# RK3399-AP register map
File version: 1
CPU: CA7 r0p1, little endian, MPU, FPU, I-cache, D-cache, VTOR, 4 interrupt priority bits, 0 interrupts
Registers are 32-bit, read-write, reset 0x0 unless marked. A register's access mark holds for its fields unless they carry their own. Offsets are from the block's base; [hi:lo] are bit positions; {n}, {i} and the like mark numbered series.

## CRU (part 3 of 3)
Base 0xFF760000
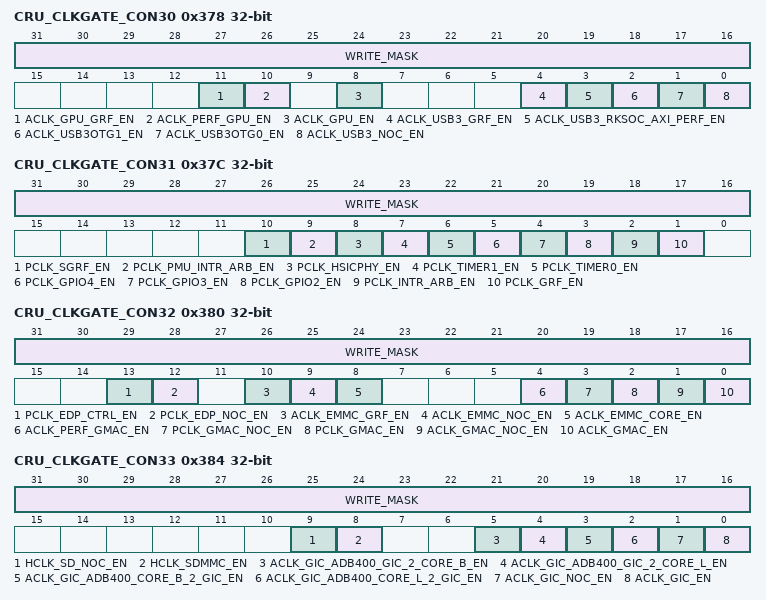
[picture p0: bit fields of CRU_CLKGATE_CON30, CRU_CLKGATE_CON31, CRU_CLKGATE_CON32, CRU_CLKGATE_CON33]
0x378 CRU_CLKGATE_CON30 access per field — Internal clock gating register30
  [31:16] WRITE_MASK wo — write mask bits When every bit HIGH, enable the writing corresponding bit When every bit LOW, don\'t care the writing corresponding bit
  [11] ACLK_GPU_GRF_EN rw — aclk_gpu_grf clock disable bit When HIGH, disable clock Suggest always on
  [10] ACLK_PERF_GPU_EN rw — aclk_perf_gpu clock disable bit When HIGH, disable clock
  [8] ACLK_GPU_EN rw — aclk_gpu clock disable bit When HIGH, disable clock
  [4] ACLK_USB3_GRF_EN rw — aclk_usb3_grf clock disable bit When HIGH, disable clock Suggest always on
  [3] ACLK_USB3_RKSOC_AXI_PERF_EN rw — aclk_usb3_rksoc_axi_perf clock disable bit When HIGH, disable clock
  [2] ACLK_USB3OTG1_EN rw — aclk_usb3otg1 clock disable bit When HIGH, disable clock
  [1] ACLK_USB3OTG0_EN rw — aclk_usb3otg0 clock disable bit When HIGH, disable clock
  [0] ACLK_USB3_NOC_EN rw — aclk_usb3_noc clock disable bit When HIGH, disable clock Suggest always on
0x37C CRU_CLKGATE_CON31 access per field — Internal clock gating register31
  [31:16] WRITE_MASK wo — write mask bits When every bit HIGH, enable the writing corresponding bit When every bit LOW, don\'t care the writing corresponding bit
  [10] PCLK_SGRF_EN rw — pclk_sgrf clock disable bit When HIGH, disable clock Suggest always on
  [9] PCLK_PMU_INTR_ARB_EN rw — pclk_pmu_intr_arb clock disable bit When HIGH, disable clock
  [8] PCLK_HSICPHY_EN rw — pclk_hsicphy clock disable bit When HIGH, disable clock
  [7] PCLK_TIMER1_EN rw — pclk_timer1 clock disable bit When HIGH, disable clock
  [6] PCLK_TIMER0_EN rw — pclk_timer0 clock disable bit When HIGH, disable clock
  [5] PCLK_GPIO4_EN rw — pclk_gpio4 clock disable bit When HIGH, disable clock
  [4] PCLK_GPIO3_EN rw — pclk_gpio3 clock disable bit When HIGH, disable clock
  [3] PCLK_GPIO2_EN rw — pclk_gpio2 clock disable bit When HIGH, disable clock
  [2] PCLK_INTR_ARB_EN rw — pclk_intr_arb clock disable bit When HIGH, disable clock
  [1] PCLK_GRF_EN rw — pclk_grf clock disable bit When HIGH, disable clock Suggest always on
0x380 CRU_CLKGATE_CON32 access per field — Internal clock gating register32
  [31:16] WRITE_MASK wo — write mask bits When every bit HIGH, enable the writing corresponding bit When every bit LOW, don\'t care the writing corresponding bit
  [13] PCLK_EDP_CTRL_EN rw — pclk_edp_ctrl clock disable bit When HIGH, disable clock
  [12] PCLK_EDP_NOC_EN rw — pclk_edp_noc clock disable bit When HIGH, disable clock Suggest always on
  [10] ACLK_EMMC_GRF_EN rw — aclk_emmc_grf clock disable bit When HIGH, disable clock Suggest always on
  [9] ACLK_EMMC_NOC_EN rw — aclk_emmc_noc clock disable bit When HIGH, disable clock Suggest always on
  [8] ACLK_EMMC_CORE_EN rw — aclk_emmc_core clock disable bit When HIGH, disable clock
  [4] ACLK_PERF_GMAC_EN rw — aclk_perf_gmac clock disable bit When HIGH, disable clock
  [3] PCLK_GMAC_NOC_EN rw — pclk_gmac_noc clock disable bit When HIGH, disable clock Suggest always on
  [2] PCLK_GMAC_EN rw — pclk_gmac clock disable bit When HIGH, disable clock
  [1] ACLK_GMAC_NOC_EN rw — aclk_gmac_noc clock disable bit When HIGH, disable clock Suggest always on
  [0] ACLK_GMAC_EN rw — aclk_gmac clock disable bit When HIGH, disable clock
0x384 CRU_CLKGATE_CON33 access per field — Internal clock gating register33
  [31:16] WRITE_MASK wo — write mask bits When every bit HIGH, enable the writing corresponding bit When every bit LOW, don\'t care the writing corresponding bit
  [9] HCLK_SD_NOC_EN rw — hclk_sd_noc clock disable bit When HIGH, disable clock Suggest always on
  [8] HCLK_SDMMC_EN rw — hclk_sdmmc clock disable bit When HIGH, disable clock
  [5] ACLK_GIC_ADB400_GIC_2_CORE_B_EN rw — aclk_gic_adb400_gic_2_core_b clock disable bit When HIGH, disable clock
  [4] ACLK_GIC_ADB400_GIC_2_CORE_L_EN rw — aclk_gic_adb400_gic_2_core_l clock disable bit When HIGH, disable clock
  [3] ACLK_GIC_ADB400_CORE_B_2_GIC_EN rw — aclk_gic_adb400_core_b_2_gic clock disable bit When HIGH, disable clock
  [2] ACLK_GIC_ADB400_CORE_L_2_GIC_EN rw — aclk_gic_adb400_core_l_2_gic clock disable bit When HIGH, disable clock
  [1] ACLK_GIC_NOC_EN rw — aclk_gic_noc clock disable bit When HIGH, disable clock Suggest always on
  [0] ACLK_GIC_EN rw — aclk_gic clock disable bit When HIGH, disable clock
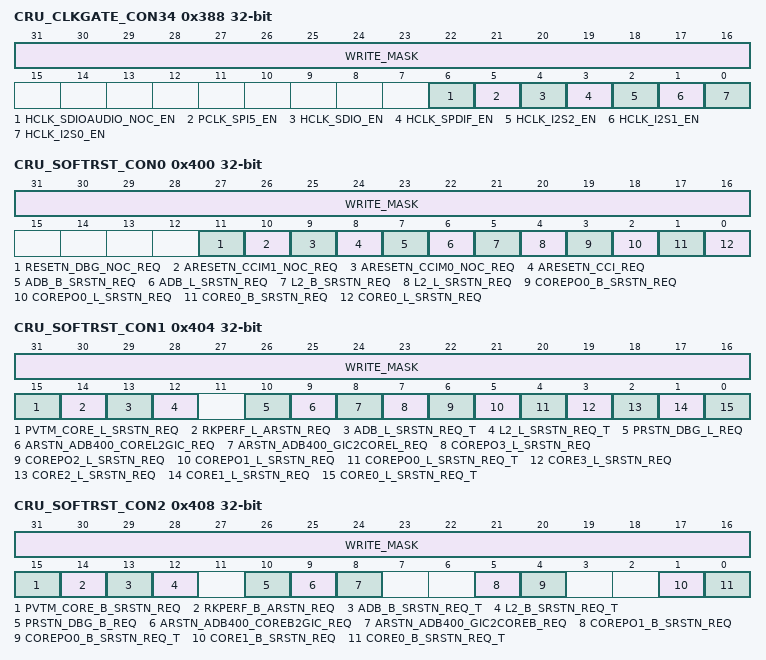
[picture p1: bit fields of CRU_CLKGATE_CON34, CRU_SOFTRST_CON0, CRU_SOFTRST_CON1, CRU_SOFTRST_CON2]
0x388 CRU_CLKGATE_CON34 access per field — Internal clock gating register34
  [31:16] WRITE_MASK wo — write mask bits When every bit HIGH, enable the writing corresponding bit When every bit LOW, don\'t care the writing corresponding bit
  [6] HCLK_SDIOAUDIO_NOC_EN rw — hclk_sdioaudio_noc clock disable bit When HIGH, disable clock Suggest always on
  [5] PCLK_SPI5_EN rw — pclk_spi5 clock disable bit When HIGH, disable clock
  [4] HCLK_SDIO_EN rw — hclk_sdio clock disable bit When HIGH, disable clock
  [3] HCLK_SPDIF_EN rw — hclk_spdif clock disable bit When HIGH, disable clock
  [2] HCLK_I2S2_EN rw — hclk_i2s2 clock disable bit When HIGH, disable clock
  [1] HCLK_I2S1_EN rw — hclk_i2s1 clock disable bit When HIGH, disable clock
  [0] HCLK_I2S0_EN rw — hclk_i2s0 clock disable bit When HIGH, disable clock
0x400 CRU_SOFTRST_CON0 wo — Internal software reset control register0
  [31:16] WRITE_MASK — write mask bits When every bit HIGH, enable the writing corresponding bit When every bit LOW, don\'t care the writing corresponding bit
  [11] RESETN_DBG_NOC_REQ write-clears — resetn_dbg_noc request bit When HIGH, reset relative logic
  [10] ARESETN_CCIM1_NOC_REQ write-clears — aresetn_ccim1_noc request bit When HIGH, reset relative logic
  [9] ARESETN_CCIM0_NOC_REQ write-clears — aresetn_ccim0_noc request bit When HIGH, reset relative logic
  [8] ARESETN_CCI_REQ write-clears — aresetn_cci request bit When HIGH, reset relative logic
  [7] ADB_B_SRSTN_REQ write-clears — adb_b_srstn request bit When HIGH, reset relative logic
  [6] ADB_L_SRSTN_REQ write-clears — adb_l_srstn request bit When HIGH, reset relative logic
  [5] L2_B_SRSTN_REQ write-clears — l2_b_srstn request bit When HIGH, reset relative logic
  [4] L2_L_SRSTN_REQ write-clears — l2_l_srstn request bit When HIGH, reset relative logic
  [3] COREPO0_B_SRSTN_REQ write-clears — corepo0_b_srstn request bit When HIGH, reset relative logic
  [2] COREPO0_L_SRSTN_REQ write-clears — corepo0_l_srstn request bit When HIGH, reset relative logic
  [1] CORE0_B_SRSTN_REQ write-clears — core0_b_srstn request bit When HIGH, reset relative logic
  [0] CORE0_L_SRSTN_REQ write-clears — core0_l_srstn request bit When HIGH, reset relative logic
0x404 CRU_SOFTRST_CON1 access per field — Internal software reset control register1
  [31:16] WRITE_MASK wo — write mask bits When every bit HIGH, enable the writing corresponding bit When every bit LOW, don\'t care the writing corresponding bit
  [15] PVTM_CORE_L_SRSTN_REQ rw — pvtm_core_l_srstn request bit When HIGH, reset relative logic
  [14] RKPERF_L_ARSTN_REQ rw — rkperf_l_arstn request bit When HIGH, reset relative logic
  [13] ADB_L_SRSTN_REQ_T rw — adb_l_srstn request bit When HIGH, reset relative logic
  [12] L2_L_SRSTN_REQ_T rw — l2_l_srstn request bit When HIGH, reset relative logic
  [10] PRSTN_DBG_L_REQ rw — prstn_dbg_l request bit When HIGH, reset relative logic
  [9] ARSTN_ADB400_COREL2GIC_REQ rw — arstn_adb400_corel2gic request bit When HIGH, reset relative logic
  [8] ARSTN_ADB400_GIC2COREL_REQ rw — arstn_adb400_gic2corel request bit When HIGH, reset relative logic
  [7] COREPO3_L_SRSTN_REQ rw — corepo3_l_srstn request bit When HIGH, reset relative logic
  [6] COREPO2_L_SRSTN_REQ rw — corepo2_l_srstn request bit When HIGH, reset relative logic
  [5] COREPO1_L_SRSTN_REQ rw — corepo1_l_srstn request bit When HIGH, reset relative logic
  [4] COREPO0_L_SRSTN_REQ_T rw — corepo0_l_srstn request bit When HIGH, reset relative logic
  [3] CORE3_L_SRSTN_REQ rw — core3_l_srstn request bit When HIGH, reset relative logic
  [2] CORE2_L_SRSTN_REQ rw — core2_l_srstn request bit When HIGH, reset relative logic
  [1] CORE1_L_SRSTN_REQ rw — core1_l_srstn request bit When HIGH, reset relative logic
  [0] CORE0_L_SRSTN_REQ_T rw — core0_l_srstn request bit When HIGH, reset relative logic
0x408 CRU_SOFTRST_CON2 access per field — Internal software reset control register2
  [31:16] WRITE_MASK wo — write mask bits When every bit HIGH, enable the writing corresponding bit When every bit LOW, don\'t care the writing corresponding bit
  [15] PVTM_CORE_B_SRSTN_REQ rw — pvtm_core_b_srstn request bit When HIGH, reset relative logic
  [14] RKPERF_B_ARSTN_REQ rw — rkperf_b_arstn request bit When HIGH, reset relative logic
  [13] ADB_B_SRSTN_REQ_T rw — adb_b_srstn request bit When HIGH, reset relative logic
  [12] L2_B_SRSTN_REQ_T rw — l2_b_srstn request bit When HIGH, reset relative logic
  [10] PRSTN_DBG_B_REQ rw — prstn_dbg_b request bit When HIGH, reset relative logic
  [9] ARSTN_ADB400_COREB2GIC_REQ rw — arstn_adb400_coreb2gic request bit When HIGH, reset relative logic
  [8] ARSTN_ADB400_GIC2COREB_REQ rw — arstn_adb400_gic2coreb request bit When HIGH, reset relative logic
  [5] COREPO1_B_SRSTN_REQ rw — corepo1_b_srstn request bit When HIGH, reset relative logic
  [4] COREPO0_B_SRSTN_REQ_T rw — corepo0_b_srstn request bit When HIGH, reset relative logic
  [1] CORE1_B_SRSTN_REQ rw — core1_b_srstn request bit When HIGH, reset relative logic
  [0] CORE0_B_SRSTN_REQ_T rw — core0_b_srstn request bit When HIGH, reset relative logic
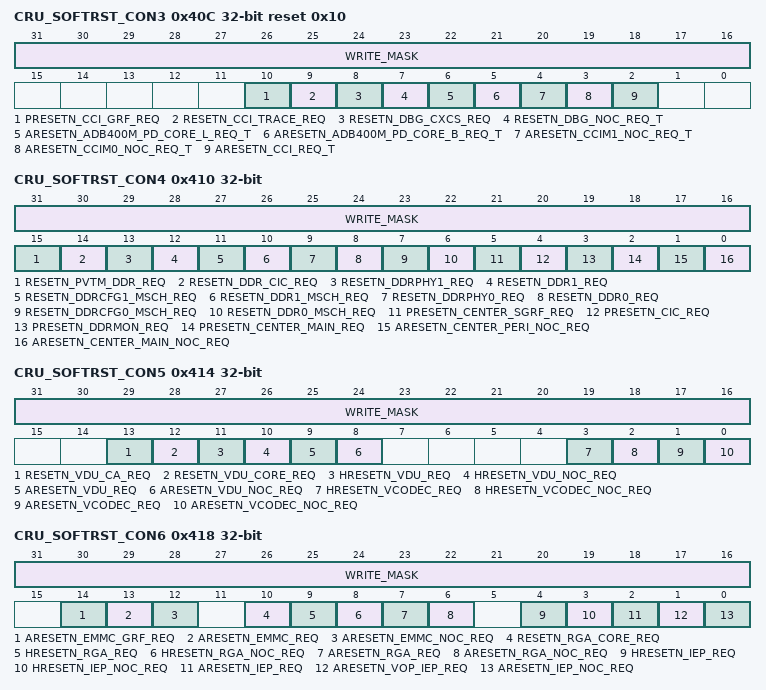
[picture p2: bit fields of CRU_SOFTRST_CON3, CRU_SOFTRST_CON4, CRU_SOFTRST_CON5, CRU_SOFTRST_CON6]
0x40C CRU_SOFTRST_CON3 access per field reset 0x10 — Internal software reset control register3
  [31:16] WRITE_MASK wo — write mask bits When every bit HIGH, enable the writing corresponding bit When every bit LOW, don\'t care the writing corresponding bit
  [10] PRESETN_CCI_GRF_REQ rw — presetn_cci_grf request bit When HIGH, reset relative logic
  [9] RESETN_CCI_TRACE_REQ rw — resetn_cci_trace request bit When HIGH, reset relative logic
  [8] RESETN_DBG_CXCS_REQ rw — resetn_dbg_cxcs request bit When HIGH, reset relative logic
  [7] RESETN_DBG_NOC_REQ_T rw — resetn_dbg_noc request bit When HIGH, reset relative logic
  [6] ARESETN_ADB400M_PD_CORE_L_REQ_T rw — aresetn_adb400m_pd_core_l request bit When HIGH, reset relative logic
  [5] ARESETN_ADB400M_PD_CORE_B_REQ_T rw — aresetn_adb400m_pd_core_b request bit When HIGH, reset relative logic
  [4] ARESETN_CCIM1_NOC_REQ_T ro — aresetn_ccim1_noc request bit When HIGH, reset relative logic
  [3] ARESETN_CCIM0_NOC_REQ_T rw — aresetn_ccim0_noc request bit When HIGH, reset relative logic
  [2] ARESETN_CCI_REQ_T rw — aresetn_cci request bit When HIGH, reset relative logic
0x410 CRU_SOFTRST_CON4 access per field — Internal software reset control register4
  [31:16] WRITE_MASK wo — write mask bits When every bit HIGH, enable the writing corresponding bit When every bit LOW, don\'t care the writing corresponding bit
  [15] RESETN_PVTM_DDR_REQ rw — resetn_pvtm_ddr request bit When HIGH, reset relative logic
  [14] RESETN_DDR_CIC_REQ rw — resetn_ddr_cic request bit When HIGH, reset relative logic
  [13] RESETN_DDRPHY1_REQ rw — resetn_ddrphy1 request bit When HIGH, reset relative logic
  [12] RESETN_DDR1_REQ rw — resetn_ddr1 request bit When HIGH, reset relative logic
  [11] RESETN_DDRCFG1_MSCH_REQ rw — resetn_ddrcfg1_msch request bit When HIGH, reset relative logic
  [10] RESETN_DDR1_MSCH_REQ rw — resetn_ddr1_msch request bit When HIGH, reset relative logic
  [9] RESETN_DDRPHY0_REQ rw — resetn_ddrphy0 request bit When HIGH, reset relative logic
  [8] RESETN_DDR0_REQ rw — resetn_ddr0 request bit When HIGH, reset relative logic
  [7] RESETN_DDRCFG0_MSCH_REQ rw — resetn_ddrcfg0_msch request bit When HIGH, reset relative logic
  [6] RESETN_DDR0_MSCH_REQ rw — resetn_ddr0_msch request bit When HIGH, reset relative logic
  [5] PRESETN_CENTER_SGRF_REQ rw — presetn_center_sgrf request bit When HIGH, reset relative logic
  [4] PRESETN_CIC_REQ rw — presetn_cic request bit When HIGH, reset relative logic
  [3] PRESETN_DDRMON_REQ rw — presetn_ddrmon request bit When HIGH, reset relative logic
  [2] PRESETN_CENTER_MAIN_REQ rw — presetn_center_main request bit When HIGH, reset relative logic
  [1] ARESETN_CENTER_PERI_NOC_REQ rw — aresetn_center_peri_noc request bit When HIGH, reset relative logic
  [0] ARESETN_CENTER_MAIN_NOC_REQ rw — aresetn_center_main_noc request bit When HIGH, reset relative logic
0x414 CRU_SOFTRST_CON5 access per field — Internal software reset control register5
  [31:16] WRITE_MASK wo — write mask bits When every bit HIGH, enable the writing corresponding bit When every bit LOW, don\'t care the writing corresponding bit
  [13] RESETN_VDU_CA_REQ rw — resetn_vdu_ca request bit When HIGH, reset relative logic
  [12] RESETN_VDU_CORE_REQ rw — resetn_vdu_core request bit When HIGH, reset relative logic
  [11] HRESETN_VDU_REQ rw — hresetn_vdu request bit When HIGH, reset relative logic
  [10] HRESETN_VDU_NOC_REQ rw — hresetn_vdu_noc request bit When HIGH, reset relative logic
  [9] ARESETN_VDU_REQ rw — aresetn_vdu request bit When HIGH, reset relative logic
  [8] ARESETN_VDU_NOC_REQ rw — aresetn_vdu_noc request bit When HIGH, reset relative logic
  [3] HRESETN_VCODEC_REQ rw — hresetn_vcodec request bit When HIGH, reset relative logic
  [2] HRESETN_VCODEC_NOC_REQ rw — hresetn_vcodec_noc request bit When HIGH, reset relative logic
  [1] ARESETN_VCODEC_REQ rw — aresetn_vcodec request bit When HIGH, reset relative logic
  [0] ARESETN_VCODEC_NOC_REQ rw — aresetn_vcodec_noc request bit When HIGH, reset relative logic
0x418 CRU_SOFTRST_CON6 access per field — Internal software reset control register6
  [31:16] WRITE_MASK wo — write mask bits When every bit HIGH, enable the writing corresponding bit When every bit LOW, don\'t care the writing corresponding bit
  [14] ARESETN_EMMC_GRF_REQ rw — aresetn_emmc_grf request bit When HIGH, reset relative logic
  [13] ARESETN_EMMC_REQ rw — aresetn_emmc request bit When HIGH, reset relative logic
  [12] ARESETN_EMMC_NOC_REQ rw — aresetn_emmc_noc request bit When HIGH, reset relative logic
  [10] RESETN_RGA_CORE_REQ rw — resetn_rga_core request bit When HIGH, reset relative logic
  [9] HRESETN_RGA_REQ rw — hresetn_rga request bit When HIGH, reset relative logic
  [8] HRESETN_RGA_NOC_REQ rw — hresetn_rga_noc request bit When HIGH, reset relative logic
  [7] ARESETN_RGA_REQ rw — aresetn_rga request bit When HIGH, reset relative logic
  [6] ARESETN_RGA_NOC_REQ rw — aresetn_rga_noc request bit When HIGH, reset relative logic
  [4] HRESETN_IEP_REQ rw — hresetn_iep request bit When HIGH, reset relative logic
  [3] HRESETN_IEP_NOC_REQ rw — hresetn_iep_noc request bit When HIGH, reset relative logic
  [2] ARESETN_IEP_REQ rw — aresetn_iep request bit When HIGH, reset relative logic
  [1] ARESETN_VOP_IEP_REQ rw — aresetn_vop_iep request bit When HIGH, reset relative logic
  [0] ARESETN_IEP_NOC_REQ rw — aresetn_iep_noc request bit When HIGH, reset relative logic
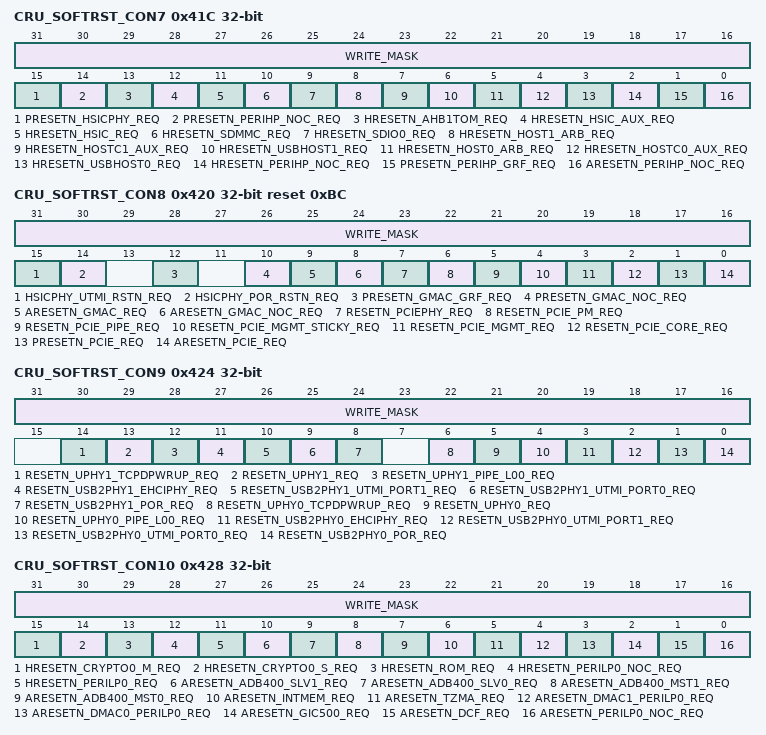
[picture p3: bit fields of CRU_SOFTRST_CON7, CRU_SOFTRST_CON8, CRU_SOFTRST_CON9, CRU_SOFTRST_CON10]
0x41C CRU_SOFTRST_CON7 access per field — Internal software reset control register7
  [31:16] WRITE_MASK wo — write mask bits When every bit HIGH, enable the writing corresponding bit When every bit LOW, don\'t care the writing corresponding bit
  [15] PRESETN_HSICPHY_REQ rw — presetn_hsicphy request bit When HIGH, reset relative logic
  [14] PRESETN_PERIHP_NOC_REQ rw — presetn_perihp_noc request bit When HIGH, reset relative logic
  [13] HRESETN_AHB1TOM_REQ rw — hresetn_ahb1tom request bit When HIGH, reset relative logic
  [12] HRESETN_HSIC_AUX_REQ rw — hresetn_hsic_aux request bit When HIGH, reset relative logic
  [11] HRESETN_HSIC_REQ rw — hresetn_hsic request bit When HIGH, reset relative logic
  [10] HRESETN_SDMMC_REQ rw — hresetn_sdmmc request bit When HIGH, reset relative logic
  [9] HRESETN_SDIO0_REQ rw — hresetn_sdio0 request bit When HIGH, reset relative logic
  [8] HRESETN_HOST1_ARB_REQ rw — hresetn_host1_arb request bit When HIGH, reset relative logic
  [7] HRESETN_HOSTC1_AUX_REQ rw — hresetn_hostc1_aux request bit When HIGH, reset relative logic
  [6] HRESETN_USBHOST1_REQ rw — hresetn_usbhost1 request bit When HIGH, reset relative logic
  [5] HRESETN_HOST0_ARB_REQ rw — hresetn_host0_arb request bit When HIGH, reset relative logic
  [4] HRESETN_HOSTC0_AUX_REQ rw — hresetn_hostc0_aux request bit When HIGH, reset relative logic
  [3] HRESETN_USBHOST0_REQ rw — hresetn_usbhost0 request bit When HIGH, reset relative logic
  [2] HRESETN_PERIHP_NOC_REQ rw — hresetn_perihp_noc request bit When HIGH, reset relative logic
  [1] PRESETN_PERIHP_GRF_REQ rw — presetn_perihp_grf request bit When HIGH, reset relative logic
  [0] ARESETN_PERIHP_NOC_REQ rw — aresetn_perihp_noc request bit When HIGH, reset relative logic
0x420 CRU_SOFTRST_CON8 access per field reset 0xBC — Internal software reset control register8
  [31:16] WRITE_MASK wo — write mask bits When every bit HIGH, enable the writing corresponding bit When every bit LOW, don\'t care the writing corresponding bit
  [15] HSICPHY_UTMI_RSTN_REQ rw — hsicphy_utmi_rstn request bit When HIGH, reset relative logic
  [14] HSICPHY_POR_RSTN_REQ rw — hsicphy_por_rstn request bit When HIGH, reset relative logic
  [12] PRESETN_GMAC_GRF_REQ rw — presetn_gmac_grf request bit When HIGH, reset relative logic
  [10] PRESETN_GMAC_NOC_REQ rw — presetn_gmac_noc request bit When HIGH, reset relative logic
  [9] ARESETN_GMAC_REQ rw — aresetn_gmac request bit When HIGH, reset relative logic
  [8] ARESETN_GMAC_NOC_REQ rw — aresetn_gmac_noc request bit When HIGH, reset relative logic
  [7] RESETN_PCIEPHY_REQ rw — resetn_pciephy request bit When HIGH, reset relative logic
  [6] RESETN_PCIE_PM_REQ rw — resetn_pcie_pm request bit When HIGH, reset relative logic
  [5] RESETN_PCIE_PIPE_REQ rw — resetn_pcie_pipe request bit When HIGH, reset relative logic
  [4] RESETN_PCIE_MGMT_STICKY_REQ rw — resetn_pcie_mgmt_sticky request bit When HIGH, reset relative logic
  [3] RESETN_PCIE_MGMT_REQ rw — resetn_pcie_mgmt request bit When HIGH, reset relative logic
  [2] RESETN_PCIE_CORE_REQ rw — resetn_pcie_core request bit When HIGH, reset relative logic
  [1] PRESETN_PCIE_REQ rw — presetn_pcie request bit When HIGH, reset relative logic
  [0] ARESETN_PCIE_REQ rw — aresetn_pcie request bit When HIGH, reset relative logic
0x424 CRU_SOFTRST_CON9 access per field — Internal software reset control register9
  [31:16] WRITE_MASK wo — write mask bits When every bit HIGH, enable the writing corresponding bit When every bit LOW, don\'t care the writing corresponding bit
  [14] RESETN_UPHY1_TCPDPWRUP_REQ rw — resetn_uphy1_tcpdpwrup request bit When HIGH, reset relative logic
  [13] RESETN_UPHY1_REQ rw — resetn_uphy1 request bit When HIGH, reset relative logic
  [12] RESETN_UPHY1_PIPE_L00_REQ rw — resetn_uphy1_pipe_l00 request bit When HIGH, reset relative logic
  [11] RESETN_USB2PHY1_EHCIPHY_REQ rw — resetn_usb2phy1_ehciphy request bit When HIGH, reset relative logic
  [10] RESETN_USB2PHY1_UTMI_PORT1_REQ rw — resetn_usb2phy1_utmi_port1 request bit When HIGH, reset relative logic
  [9] RESETN_USB2PHY1_UTMI_PORT0_REQ rw — resetn_usb2phy1_utmi_port0 request bit When HIGH, reset relative logic
  [8] RESETN_USB2PHY1_POR_REQ rw — resetn_usb2phy1_por request bit When HIGH, reset relative logic
  [6] RESETN_UPHY0_TCPDPWRUP_REQ rw — resetn_uphy0_tcpdpwrup request bit When HIGH, reset relative logic
  [5] RESETN_UPHY0_REQ rw — resetn_uphy0 request bit When HIGH, reset relative logic
  [4] RESETN_UPHY0_PIPE_L00_REQ rw — resetn_uphy0_pipe_l00 request bit When HIGH, reset relative logic
  [3] RESETN_USB2PHY0_EHCIPHY_REQ rw — resetn_usb2phy0_ehciphy request bit When HIGH, reset relative logic
  [2] RESETN_USB2PHY0_UTMI_PORT1_REQ rw — resetn_usb2phy0_utmi_port1 request bit When HIGH, reset relative logic
  [1] RESETN_USB2PHY0_UTMI_PORT0_REQ rw — resetn_usb2phy0_utmi_port0 request bit When HIGH, reset relative logic
  [0] RESETN_USB2PHY0_POR_REQ rw — resetn_usb2phy0_por request bit When HIGH, reset relative logic
0x428 CRU_SOFTRST_CON10 access per field — Internal software reset control register10
  [31:16] WRITE_MASK wo — write mask bits When every bit HIGH, enable the writing corresponding bit When every bit LOW, don\'t care the writing corresponding bit
  [15] HRESETN_CRYPTO0_M_REQ rw — hresetn_crypto0_m request bit When HIGH, reset relative logic
  [14] HRESETN_CRYPTO0_S_REQ rw — hresetn_crypto0_s request bit When HIGH, reset relative logic
  [13] HRESETN_ROM_REQ rw — hresetn_rom request bit When HIGH, reset relative logic
  [12] HRESETN_PERILP0_NOC_REQ rw — hresetn_perilp0_noc request bit When HIGH, reset relative logic
  [11] HRESETN_PERILP0_REQ rw — hresetn_perilp0 request bit When HIGH, reset relative logic
  [10] ARESETN_ADB400_SLV1_REQ rw — aresetn_adb400_slv1 request bit When HIGH, reset relative logic
  [9] ARESETN_ADB400_SLV0_REQ rw — aresetn_adb400_slv0 request bit When HIGH, reset relative logic
  [8] ARESETN_ADB400_MST1_REQ rw — aresetn_adb400_mst1 request bit When HIGH, reset relative logic
  [7] ARESETN_ADB400_MST0_REQ rw — aresetn_adb400_mst0 request bit When HIGH, reset relative logic
  [6] ARESETN_INTMEM_REQ rw — aresetn_intmem request bit When HIGH, reset relative logic
  [5] ARESETN_TZMA_REQ rw — aresetn_tzma request bit When HIGH, reset relative logic
  [4] ARESETN_DMAC1_PERILP0_REQ rw — aresetn_dmac1_perilp0 request bit When HIGH, reset relative logic
  [3] ARESETN_DMAC0_PERILP0_REQ rw — aresetn_dmac0_perilp0 request bit When HIGH, reset relative logic
  [2] ARESETN_GIC500_REQ rw — aresetn_gic500 request bit When HIGH, reset relative logic
  [1] ARESETN_DCF_REQ rw — aresetn_dcf request bit When HIGH, reset relative logic
  [0] ARESETN_PERILP0_NOC_REQ rw — aresetn_perilp0_noc request bit When HIGH, reset relative logic
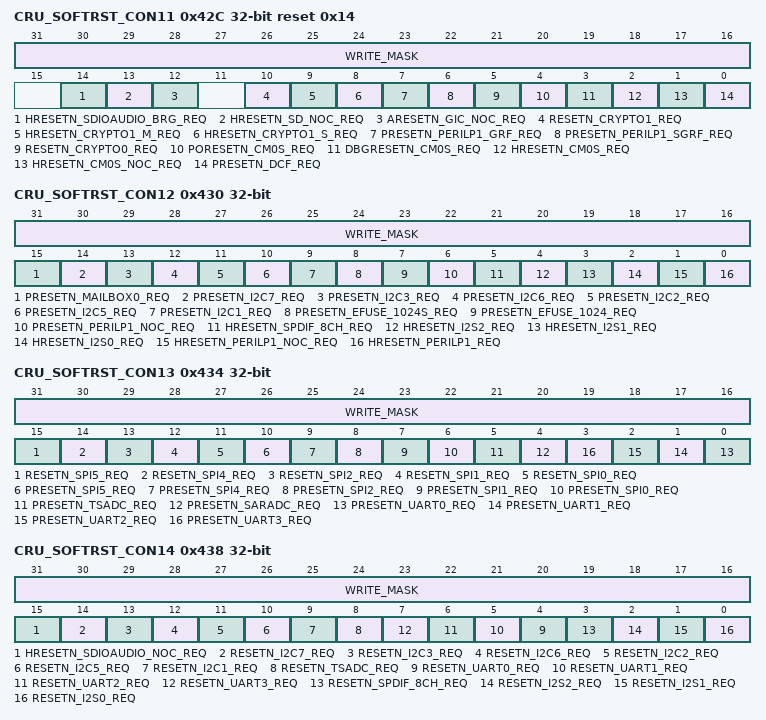
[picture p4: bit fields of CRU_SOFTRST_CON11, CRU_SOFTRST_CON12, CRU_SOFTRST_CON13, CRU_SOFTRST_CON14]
0x42C CRU_SOFTRST_CON11 access per field reset 0x14 — Internal software reset control register11
  [31:16] WRITE_MASK wo — write mask bits When every bit HIGH, enable the writing corresponding bit When every bit LOW, don\'t care the writing corresponding bit
  [14] HRESETN_SDIOAUDIO_BRG_REQ rw — hresetn_sdioaudio_brg request bit When HIGH, reset relative logic
  [13] HRESETN_SD_NOC_REQ rw — hresetn_sd_noc request bit When HIGH, reset relative logic
  [12] ARESETN_GIC_NOC_REQ rw — aresetn_gic_noc request bit When HIGH, reset relative logic
  [10] RESETN_CRYPTO1_REQ rw — resetn_crypto1 request bit When HIGH, reset relative logic
  [9] HRESETN_CRYPTO1_M_REQ rw — hresetn_crypto1_m request bit When HIGH, reset relative logic
  [8] HRESETN_CRYPTO1_S_REQ rw — hresetn_crypto1_s request bit When HIGH, reset relative logic
  [7] PRESETN_PERILP1_GRF_REQ rw — presetn_perilp1_grf request bit When HIGH, reset relative logic
  [6] PRESETN_PERILP1_SGRF_REQ rw — presetn_perilp1_sgrf request bit When HIGH, reset relative logic
  [5] RESETN_CRYPTO0_REQ rw — resetn_crypto0 request bit When HIGH, reset relative logic
  [4] PORESETN_CM0S_REQ rw — poresetn_cm0s request bit When HIGH, reset relative logic
  [3] DBGRESETN_CM0S_REQ rw — dbgresetn_cm0s request bit When HIGH, reset relative logic
  [2] HRESETN_CM0S_REQ rw — hresetn_cm0s request bit When HIGH, reset relative logic
  [1] HRESETN_CM0S_NOC_REQ rw — hresetn_cm0s_noc request bit When HIGH, reset relative logic
  [0] PRESETN_DCF_REQ rw — presetn_dcf request bit When HIGH, reset relative logic
0x430 CRU_SOFTRST_CON12 access per field — Internal software reset control register12
  [31:16] WRITE_MASK wo — write mask bits When every bit HIGH, enable the writing corresponding bit When every bit LOW, don\'t care the writing corresponding bit
  [15] PRESETN_MAILBOX0_REQ rw — presetn_mailbox0 request bit When HIGH, reset relative logic
  [14] PRESETN_I2C7_REQ rw — presetn_i2c7 request bit When HIGH, reset relative logic
  [13] PRESETN_I2C3_REQ rw — presetn_i2c3 request bit When HIGH, reset relative logic
  [12] PRESETN_I2C6_REQ rw — presetn_i2c6 request bit When HIGH, reset relative logic
  [11] PRESETN_I2C2_REQ rw — presetn_i2c2 request bit When HIGH, reset relative logic
  [10] PRESETN_I2C5_REQ rw — presetn_i2c5 request bit When HIGH, reset relative logic
  [9] PRESETN_I2C1_REQ rw — presetn_i2c1 request bit When HIGH, reset relative logic
  [8] PRESETN_EFUSE_1024S_REQ rw — presetn_efuse_1024s request bit When HIGH, reset relative logic
  [7] PRESETN_EFUSE_1024_REQ rw — presetn_efuse_1024 request bit When HIGH, reset relative logic
  [6] PRESETN_PERILP1_NOC_REQ rw — presetn_perilp1_noc request bit When HIGH, reset relative logic
  [5] HRESETN_SPDIF_8CH_REQ rw — hresetn_spdif_8ch request bit When HIGH, reset relative logic
  [4] HRESETN_I2S2_REQ rw — hresetn_i2s2 request bit When HIGH, reset relative logic
  [3] HRESETN_I2S1_REQ rw — hresetn_i2s1 request bit When HIGH, reset relative logic
  [2] HRESETN_I2S0_REQ rw — hresetn_i2s0 request bit When HIGH, reset relative logic
  [1] HRESETN_PERILP1_NOC_REQ rw — hresetn_perilp1_noc request bit When HIGH, reset relative logic
  [0] HRESETN_PERILP1_REQ rw — hresetn_perilp1 request bit When HIGH, reset relative logic
0x434 CRU_SOFTRST_CON13 access per field — Internal software reset control register13
  [31:16] WRITE_MASK wo — write mask bits When every bit HIGH, enable the writing corresponding bit When every bit LOW, don\'t care the writing corresponding bit
  [15] RESETN_SPI5_REQ rw — resetn_spi5 request bit When HIGH, reset relative logic
  [14] RESETN_SPI4_REQ rw — resetn_spi4 request bit When HIGH, reset relative logic
  [13] RESETN_SPI2_REQ rw — resetn_spi2 request bit When HIGH, reset relative logic
  [12] RESETN_SPI1_REQ rw — resetn_spi1 request bit When HIGH, reset relative logic
  [11] RESETN_SPI0_REQ rw — resetn_spi0 request bit When HIGH, reset relative logic
  [10] PRESETN_SPI5_REQ rw — presetn_spi5 request bit When HIGH, reset relative logic
  [9] PRESETN_SPI4_REQ rw — presetn_spi4 request bit When HIGH, reset relative logic
  [8] PRESETN_SPI2_REQ rw — presetn_spi2 request bit When HIGH, reset relative logic
  [7] PRESETN_SPI1_REQ rw — presetn_spi1 request bit When HIGH, reset relative logic
  [6] PRESETN_SPI0_REQ rw — presetn_spi0 request bit When HIGH, reset relative logic
  [5] PRESETN_TSADC_REQ rw — presetn_tsadc request bit When HIGH, reset relative logic
  [4] PRESETN_SARADC_REQ rw — presetn_saradc request bit When HIGH, reset relative logic
  [n] PRESETN_UART{n}_REQ rw (n=0..3) — presetn_uart{n} request bit When HIGH, reset relative logic
0x438 CRU_SOFTRST_CON14 access per field — Internal software reset control register14
  [31:16] WRITE_MASK wo — write mask bits When every bit HIGH, enable the writing corresponding bit When every bit LOW, don\'t care the writing corresponding bit
  [15] HRESETN_SDIOAUDIO_NOC_REQ rw — hresetn_sdioaudio_noc request bit When HIGH, reset relative logic
  [14] RESETN_I2C7_REQ rw — resetn_i2c7 request bit When HIGH, reset relative logic
  [13] RESETN_I2C3_REQ rw — resetn_i2c3 request bit When HIGH, reset relative logic
  [12] RESETN_I2C6_REQ rw — resetn_i2c6 request bit When HIGH, reset relative logic
  [11] RESETN_I2C2_REQ rw — resetn_i2c2 request bit When HIGH, reset relative logic
  [10] RESETN_I2C5_REQ rw — resetn_i2c5 request bit When HIGH, reset relative logic
  [9] RESETN_I2C1_REQ rw — resetn_i2c1 request bit When HIGH, reset relative logic
  [8] RESETN_TSADC_REQ rw — resetn_tsadc request bit When HIGH, reset relative logic
  [n+4] RESETN_UART{n}_REQ rw (n=0..3) — resetn_uart{n} request bit When HIGH, reset relative logic
  [3] RESETN_SPDIF_8CH_REQ rw — resetn_spdif_8ch request bit When HIGH, reset relative logic
  [2] RESETN_I2S2_REQ rw — resetn_i2s2 request bit When HIGH, reset relative logic
  [1] RESETN_I2S1_REQ rw — resetn_i2s1 request bit When HIGH, reset relative logic
  [0] RESETN_I2S0_REQ rw — resetn_i2s0 request bit When HIGH, reset relative logic
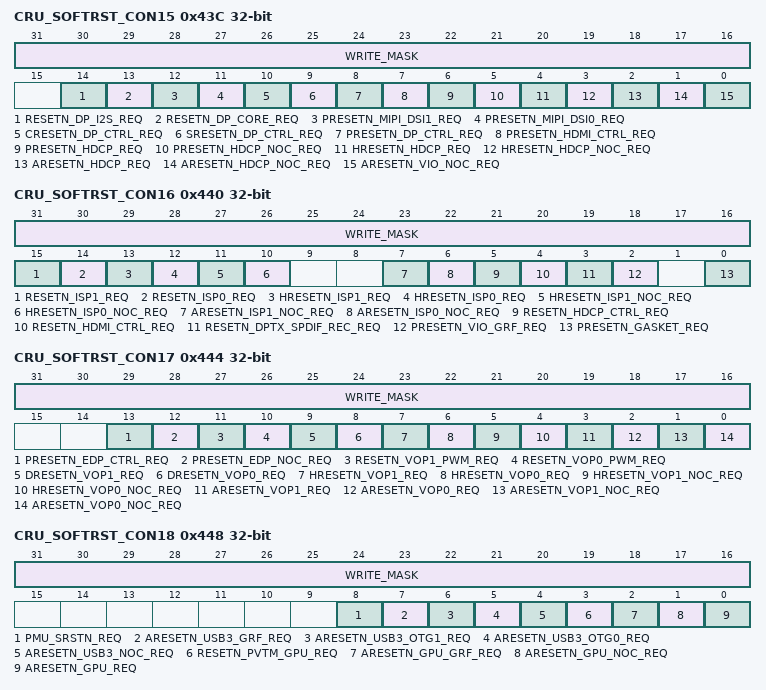
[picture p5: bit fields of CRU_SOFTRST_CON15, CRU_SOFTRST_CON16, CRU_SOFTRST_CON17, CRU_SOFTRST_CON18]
0x43C CRU_SOFTRST_CON15 access per field — Internal software reset control register15
  [31:16] WRITE_MASK wo — write mask bits When every bit HIGH, enable the writing corresponding bit When every bit LOW, don\'t care the writing corresponding bit
  [14] RESETN_DP_I2S_REQ rw — resetn_dp_i2s request bit When HIGH, reset relative logic
  [13] RESETN_DP_CORE_REQ rw — resetn_dp_core request bit When HIGH, reset relative logic
  [12] PRESETN_MIPI_DSI1_REQ rw — presetn_mipi_dsi1 request bit When HIGH, reset relative logic
  [11] PRESETN_MIPI_DSI0_REQ rw — presetn_mipi_dsi0 request bit When HIGH, reset relative logic
  [10] CRESETN_DP_CTRL_REQ rw — cresetn_dp_ctrl request bit When HIGH, reset relative logic
  [9] SRESETN_DP_CTRL_REQ rw — sresetn_dp_ctrl request bit When HIGH, reset relative logic
  [8] PRESETN_DP_CTRL_REQ rw — presetn_dp_ctrl request bit When HIGH, reset relative logic
  [7] PRESETN_HDMI_CTRL_REQ rw — presetn_hdmi_ctrl request bit When HIGH, reset relative logic
  [6] PRESETN_HDCP_REQ rw — presetn_hdcp request bit When HIGH, reset relative logic
  [5] PRESETN_HDCP_NOC_REQ rw — presetn_hdcp_noc request bit When HIGH, reset relative logic
  [4] HRESETN_HDCP_REQ rw — hresetn_hdcp request bit When HIGH, reset relative logic
  [3] HRESETN_HDCP_NOC_REQ rw — hresetn_hdcp_noc request bit When HIGH, reset relative logic
  [2] ARESETN_HDCP_REQ rw — aresetn_hdcp request bit When HIGH, reset relative logic
  [1] ARESETN_HDCP_NOC_REQ rw — aresetn_hdcp_noc request bit When HIGH, reset relative logic
  [0] ARESETN_VIO_NOC_REQ rw — aresetn_vio_noc request bit When HIGH, reset relative logic
0x440 CRU_SOFTRST_CON16 access per field — Internal software reset control register16
  [31:16] WRITE_MASK wo — write mask bits When every bit HIGH, enable the writing corresponding bit When every bit LOW, don\'t care the writing corresponding bit
  [15] RESETN_ISP1_REQ rw — resetn_isp1 request bit When HIGH, reset relative logic
  [14] RESETN_ISP0_REQ rw — resetn_isp0 request bit When HIGH, reset relative logic
  [13] HRESETN_ISP1_REQ rw — hresetn_isp1 request bit When HIGH, reset relative logic
  [12] HRESETN_ISP0_REQ rw — hresetn_isp0 request bit When HIGH, reset relative logic
  [11] HRESETN_ISP1_NOC_REQ rw — hresetn_isp1_noc request bit When HIGH, reset relative logic
  [10] HRESETN_ISP0_NOC_REQ rw — hresetn_isp0_noc request bit When HIGH, reset relative logic
  [7] ARESETN_ISP1_NOC_REQ rw — aresetn_isp1_noc request bit When HIGH, reset relative logic
  [6] ARESETN_ISP0_NOC_REQ rw — aresetn_isp0_noc request bit When HIGH, reset relative logic
  [5] RESETN_HDCP_CTRL_REQ rw — resetn_hdcp_ctrl request bit When HIGH, reset relative logic
  [4] RESETN_HDMI_CTRL_REQ rw — resetn_hdmi_ctrl request bit When HIGH, reset relative logic
  [3] RESETN_DPTX_SPDIF_REC_REQ rw — resetn_dptx_spdif_rec request bit When HIGH, reset relative logic
  [2] PRESETN_VIO_GRF_REQ rw — presetn_vio_grf request bit When HIGH, reset relative logic
  [0] PRESETN_GASKET_REQ rw — presetn_gasket request bit When HIGH, reset relative logic
0x444 CRU_SOFTRST_CON17 access per field — Internal software reset control register17
  [31:16] WRITE_MASK wo — write mask bits When every bit HIGH, enable the writing corresponding bit When every bit LOW, don\'t care the writing corresponding bit
  [13] PRESETN_EDP_CTRL_REQ rw — presetn_edp_ctrl request bit When HIGH, reset relative logic
  [12] PRESETN_EDP_NOC_REQ rw — presetn_edp_noc request bit When HIGH, reset relative logic
  [11] RESETN_VOP1_PWM_REQ rw — resetn_vop1_pwm request bit When HIGH, reset relative logic
  [10] RESETN_VOP0_PWM_REQ rw — resetn_vop0_pwm request bit When HIGH, reset relative logic
  [9] DRESETN_VOP1_REQ rw — dresetn_vop1 request bit When HIGH, reset relative logic
  [8] DRESETN_VOP0_REQ rw — dresetn_vop0 request bit When HIGH, reset relative logic
  [7] HRESETN_VOP1_REQ rw — hresetn_vop1 request bit When HIGH, reset relative logic
  [6] HRESETN_VOP0_REQ rw — hresetn_vop0 request bit When HIGH, reset relative logic
  [5] HRESETN_VOP1_NOC_REQ rw — hresetn_vop1_noc request bit When HIGH, reset relative logic
  [4] HRESETN_VOP0_NOC_REQ rw — hresetn_vop0_noc request bit When HIGH, reset relative logic
  [3] ARESETN_VOP1_REQ rw — aresetn_vop1 request bit When HIGH, reset relative logic
  [2] ARESETN_VOP0_REQ rw — aresetn_vop0 request bit When HIGH, reset relative logic
  [1] ARESETN_VOP1_NOC_REQ rw — aresetn_vop1_noc request bit When HIGH, reset relative logic
  [0] ARESETN_VOP0_NOC_REQ rw — aresetn_vop0_noc request bit When HIGH, reset relative logic
0x448 CRU_SOFTRST_CON18 access per field — Internal software reset control register18
  [31:16] WRITE_MASK wo — write mask bits When every bit HIGH, enable the writing corresponding bit When every bit LOW, don\'t care the writing corresponding bit
  [8] PMU_SRSTN_REQ rw — pmu_srstn request bit When HIGH, reset relative logic
  [7] ARESETN_USB3_GRF_REQ rw — aresetn_usb3_grf request bit When HIGH, reset relative logic
  [6] ARESETN_USB3_OTG1_REQ rw — aresetn_usb3_otg1 request bit When HIGH, reset relative logic
  [5] ARESETN_USB3_OTG0_REQ rw — aresetn_usb3_otg0 request bit When HIGH, reset relative logic
  [4] ARESETN_USB3_NOC_REQ rw — aresetn_usb3_noc request bit When HIGH, reset relative logic
  [3] RESETN_PVTM_GPU_REQ rw — resetn_pvtm_gpu request bit When HIGH, reset relative logic
  [2] ARESETN_GPU_GRF_REQ rw — aresetn_gpu_grf request bit When HIGH, reset relative logic
  [1] ARESETN_GPU_NOC_REQ rw — aresetn_gpu_noc request bit When HIGH, reset relative logic
  [0] ARESETN_GPU_REQ rw — aresetn_gpu request bit When HIGH, reset relative logic
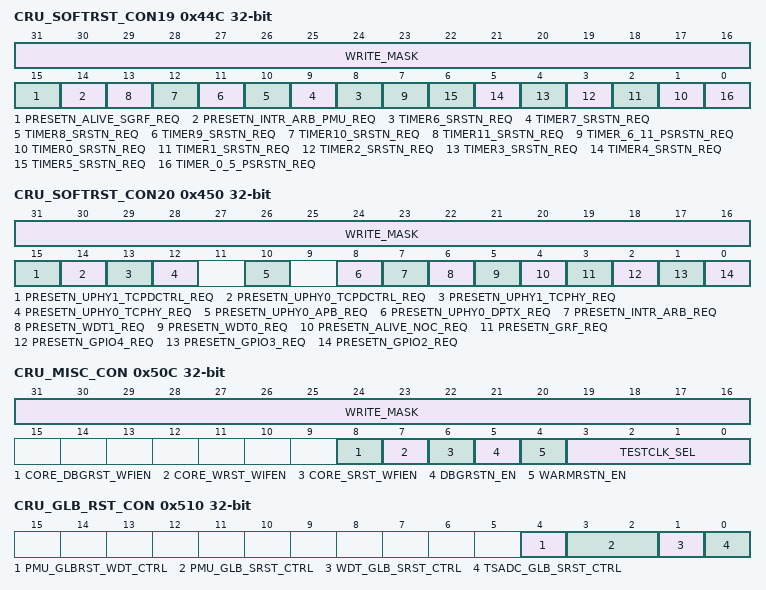
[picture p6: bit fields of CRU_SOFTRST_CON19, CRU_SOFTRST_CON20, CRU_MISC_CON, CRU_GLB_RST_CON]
0x44C CRU_SOFTRST_CON19 access per field — Internal software reset control register19
  [31:16] WRITE_MASK wo — write mask bits When every bit HIGH, enable the writing corresponding bit When every bit LOW, don\'t care the writing corresponding bit
  [15] PRESETN_ALIVE_SGRF_REQ rw — presetn_alive_sgrf request bit When HIGH, reset relative logic
  [14] PRESETN_INTR_ARB_PMU_REQ rw — presetn_intr_arb_pmu request bit When HIGH, reset relative logic
  [n+2] TIMER{n}_SRSTN_REQ rw (n=6..11) — timer{n}_srstn request bit When HIGH, reset relative logic
  [7] TIMER_6_11_PSRSTN_REQ rw — timer_6_11_psrstn request bit When HIGH, reset relative logic
  [n+1] TIMER{n}_SRSTN_REQ rw (n=0..5) — timer{n}_srstn request bit When HIGH, reset relative logic
  [0] TIMER_0_5_PSRSTN_REQ rw — timer_0_5_psrstn request bit When HIGH, reset relative logic
0x450 CRU_SOFTRST_CON20 access per field — Internal software reset control register20
  [31:16] WRITE_MASK wo — write mask bits When every bit HIGH, enable the writing corresponding bit When every bit LOW, don\'t care the writing corresponding bit
  [15] PRESETN_UPHY1_TCPDCTRL_REQ rw — presetn_uphy1_tcpdctrl request bit When HIGH, reset relative logic
  [14] PRESETN_UPHY0_TCPDCTRL_REQ rw — presetn_uphy0_tcpdctrl request bit When HIGH, reset relative logic
  [13] PRESETN_UPHY1_TCPHY_REQ rw — presetn_uphy1_tcphy request bit When HIGH, reset relative logic
  [12] PRESETN_UPHY0_TCPHY_REQ rw — presetn_uphy0_tcphy request bit When HIGH, reset relative logic
  [10] PRESETN_UPHY0_APB_REQ rw — presetn_uphy0_apb request bit When HIGH, reset relative logic
  [8] PRESETN_UPHY0_DPTX_REQ rw — presetn_uphy0_dptx request bit When HIGH, reset relative logic
  [7] PRESETN_INTR_ARB_REQ rw — presetn_intr_arb request bit When HIGH, reset relative logic
  [6] PRESETN_WDT1_REQ rw — presetn_wdt1 request bit When HIGH, reset relative logic
  [5] PRESETN_WDT0_REQ rw — presetn_wdt0 request bit When HIGH, reset relative logic
  [4] PRESETN_ALIVE_NOC_REQ rw — presetn_alive_noc request bit When HIGH, reset relative logic
  [3] PRESETN_GRF_REQ rw — presetn_grf request bit When HIGH, reset relative logic
  [2] PRESETN_GPIO4_REQ rw — presetn_gpio4 request bit When HIGH, reset relative logic
  [1] PRESETN_GPIO3_REQ rw — presetn_gpio3 request bit When HIGH, reset relative logic
  [0] PRESETN_GPIO2_REQ rw — presetn_gpio2 request bit When HIGH, reset relative logic
0x500 CRU_GLB_SRST_FST_VALUE — The first global software reset config value
  [15:0] GLB_SRST_FST_VALUE — The first global software reset config value If config 0xfdb9, it will generate first global software reset
0x504 CRU_GLB_SRST_SND_VALUE — The second global software reset config value
  [15:0] GLB_SRST_SND_VALUE — The second global software reset config value If config 0xeca8, it will generate second global software reset
0x508 CRU_GLB_CNT_TH — Global soft reset counter threshold
  [9:0] GLB_RST_CNT_TH — global reset wait counter threshold wait cycles n(at xin_24m)
0x50C CRU_MISC_CON access per field — Output clock selection for test
  [31:16] WRITE_MASK wo — write mask bits When every bit HIGH, enable the writing corresponding bit When every bit LOW, don\'t care the writing corresponding bit
  [8] CORE_DBGRST_WFIEN rw — A53/A72 dbg reset wait for STANDBYWFI enable 1\'b0 : A53 dbg reset has no relation to STANDBYWFI status 1\'b1 : A53 dgb reset is asserted after STANDBYWFI valid
  [7] CORE_WRST_WIFEN rw — A53/A72 warm reset wait for STANDBYWFI enable 1\'b0 : A53/A72 warm reset has no relation to STANDBYWFI status 1\'b1 : A53/A72 warm reset is asserted after STANDBYWFI valid
  [6] CORE_SRST_WFIEN rw — A53/A72 software reset wait for STANDBYWFI enable 1\'b0 : A53/A72 software reset has no relation to STANDBYWFI status 1\'b1 : A53/A72 software reset is asserted after STANDBYWFI valid
  [5] DBGRSTN_EN rw — A53/A72 DBGRSTN reset enable 1\'b0 : disable A53/A72 DBGRSTN reset 1\'b1 : enable A53/A72 DBGRSTN reset
  [4] WARMRSTN_EN rw — A53/A72 warm reset enable 1\'b0 : disable A53/A72 warm reset 1\'b1 : enable A53/A72 warm reset
  [3:0] TESTCLK_SEL rw — Output clock selection for test 4\'h0: clk_core_b_2wrap 4\'h1: clk_core_l_2wrap 4\'h2: aclk_cci_2wrap 4\'h3: aclk_perihp_2wrap 4\'h4: aclk_perilp0_2wrap 4\'h5: hclk_perilp1_2wrap 4\'h6: aclk_center_2wrap 4\'h7: clk_ddrc_2wrap 4\'h8: aclk_gpu_2wrap 4\'h9: clk_rga_core_2wrap 4\'ha: clk_vdu_core_2wrap 4\'hb: clk_pciephy_ref100m 4\'hc: dclk_vop0_2wrap 4\'hd: clk_rtc 4\'he: clkout_24m 4\'hf: clk_wifi
0x510 CRU_GLB_RST_CON — Global reset trigger select
  [4] PMU_GLBRST_WDT_CTRL — if pmu reset by wdt resetn src select 1\'b0: pmu reset by wdt rstn 1\'b1: pmu does not reset by wdt rstn
  [3:2] PMU_GLB_SRST_CTRL — pmu reset by global soft reset select 2\'b00: pmu reset by first global soft reset 2\'b01: pmu reset by second global soft reset 2\'b10: pmu not reset by any global soft reset
  [1] WDT_GLB_SRST_CTRL — watch_dog trigger global soft reset select 1\'b0: watch_dog trigger second global reset 1\'b1: watch_dog trigger first global reset
  [0] TSADC_GLB_SRST_CTRL — TSADC trigger global soft reset select 1\'b0: tsadc trigger second global reset 1\'b1: tsadc trigger first global reset
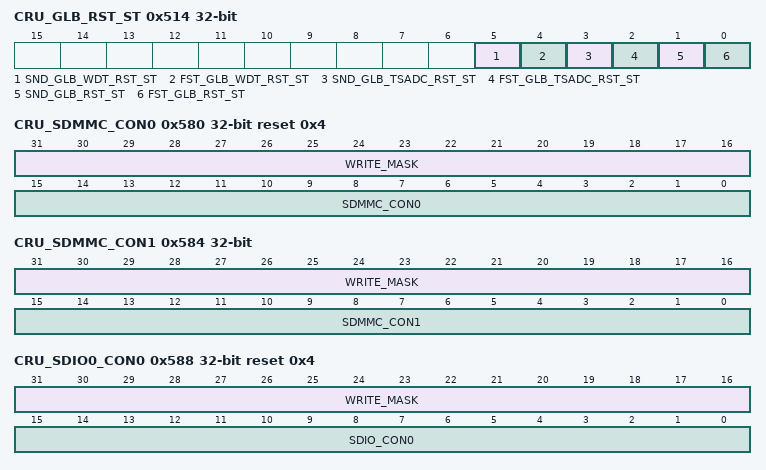
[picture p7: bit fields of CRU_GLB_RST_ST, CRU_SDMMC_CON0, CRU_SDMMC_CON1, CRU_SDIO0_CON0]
0x514 CRU_GLB_RST_ST — Global reset status
  [5] SND_GLB_WDT_RST_ST write-1-clears — second global watch_dog triggered reset flag 1\'b0: last hot reset is not second global watch_dog triggered reset 1\'b1: last hot reset is second global watch_dog triggered reset
  [4] FST_GLB_WDT_RST_ST write-1-clears — first global watch_dog triggered reset flag 1\'b0: last hot reset is not first global watch_dog triggered reset 1\'b1: last hot reset is first global watch_dog triggered reset
  [3] SND_GLB_TSADC_RST_ST write-1-clears — second global TSADC triggered reset flag 1\'b0: last hot reset is not second global TSADC triggered reset 1\'b1: last hot reset is second global TSADC triggered reset
  [2] FST_GLB_TSADC_RST_ST write-1-clears — first global TSADC triggered reset flag 1\'b0: last hot reset is not first global TSADC triggered reset 1\'b1: last hot reset is first global TSADC triggered reset
  [1] SND_GLB_RST_ST write-1-clears — second global rst flag 1\'b0: last hot reset is not second global reset 1\'b1: last hot reset is second global reset
  [0] FST_GLB_RST_ST write-1-clears — first global rst flag 1\'b0: last hot reset is not first global reset 1\'b1: last hot reset is first global reset
0x580 CRU_SDMMC_CON0 wo reset 0x4 — sdmmc control0
  [31:16] WRITE_MASK — write mask bits When every bit HIGH, enable the writing corresponding bit When every bit LOW, don\'t care the writing corresponding bit
  [15:0] SDMMC_CON0 — sdmmc con0 register refer to chapter SDMMC
0x584 CRU_SDMMC_CON1 wo — sdmmc control1
  [31:16] WRITE_MASK — write mask bits When every bit HIGH, enable the writing corresponding bit When every bit LOW, don\'t care the writing corresponding bit
  [15:0] SDMMC_CON1 — sdmmc con1 register refer to chapter SDMMC
0x588 CRU_SDIO0_CON0 wo reset 0x4 — sdio0 control0
  [31:16] WRITE_MASK — write mask bits When every bit HIGH, enable the writing corresponding bit When every bit LOW, don\'t care the writing corresponding bit
  [15:0] SDIO_CON0 — sdio_con0 register refer to chapter SDIO
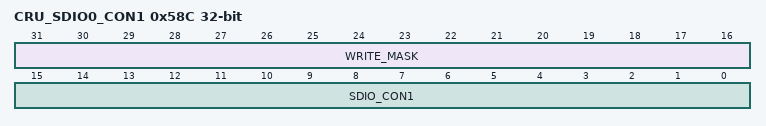
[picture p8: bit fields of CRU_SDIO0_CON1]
0x58C CRU_SDIO0_CON1 wo — sdio0 control1
  [31:16] WRITE_MASK — write mask bits When every bit HIGH, enable the writing corresponding bit When every bit LOW, don\'t care the writing corresponding bit
  [15:0] SDIO_CON1 — sdio_con1 register refer to chapter SDIO
